# DECODER0_PVDEC_ENTROPY_HEVC register map
Vendor: Texas Instruments
Peripheral module from a debugger description file (folder J7ES).
Registers are 32-bit, read-write, reset 0x0 unless marked. A register's access mark holds for its fields unless they carry their own. Offsets are as the file gives them; lines under a group give offsets from that group; [hi:lo] are bit positions; {n}, {i} and the like mark numbered series; 'fields as' and 'values as' point back to an identical list; <NAME> marks a mode.

## DECODER0_PVDEC_ENTROPY_HEVC
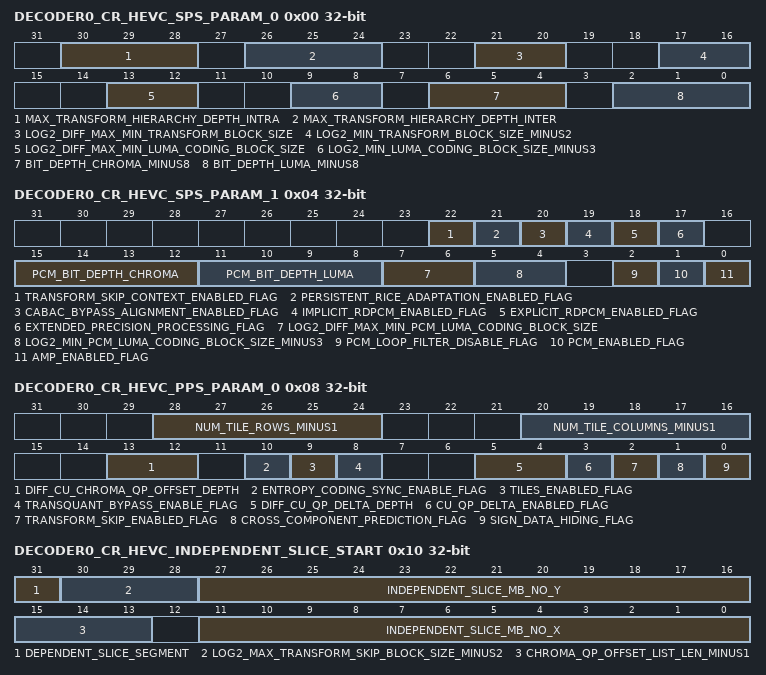
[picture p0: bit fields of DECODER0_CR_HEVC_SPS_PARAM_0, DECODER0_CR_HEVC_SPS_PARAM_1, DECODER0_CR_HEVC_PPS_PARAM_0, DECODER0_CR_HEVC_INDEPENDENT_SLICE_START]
0x00 DECODER0_CR_HEVC_SPS_PARAM_0
  [30:28] MAX_TRANSFORM_HIERARCHY_DEPTH_INTRA — Defines the maximum hierarchy depth an Intra Coded block can be split into smaller transforms [cannot be gretaer than Log2CtbSizeY [maximum is
  [26:24] MAX_TRANSFORM_HIERARCHY_DEPTH_INTER — Defines the maximum hierarchy depth an Inter Coded block can be split into smaller transforms [cannot be gretaer than Log2CtbSizeY [maximum is
  [21:20] LOG2_DIFF_MAX_MIN_TRANSFORM_BLOCK_SIZE — Defines the difference between minimum and maximum transform block size [where LOG2_MIN_TRANSFORM_BLOCK_SIZE_MINUS2 + LOG2_DIFF_MAX_MIN_TRANSFORM_BLOCK_SIZE must be &lt;= 3, and must also be less than or equal to the maximum coded block size]
  [17:16] LOG2_MIN_TRANSFORM_BLOCK_SIZE_MINUS2 — Defines the minimum transform block size [where the minimum transform block size can not be greater than the minimum luma coded block size]
  [13:12] LOG2_DIFF_MAX_MIN_LUMA_CODING_BLOCK_SIZE — Defines the difference between minimum and maximum luma coded block size, where the resulting size is sometimes refered to as the Coded Tree Unit size or CTU_SIZE [where for Main Profile, LOG2_MIN_LUMA_CODING_BLOCK_SIZE_MINUS3 + LOG2_DIFF_MAX_MIN_LUMA_CODING_BLOCK_SIZE will be in the range 1 to 3]
  [9:8] LOG2_MIN_LUMA_CODING_BLOCK_SIZE_MINUS3 — Defines the minimum luma coded block size
  [6:4] BIT_DEPTH_CHROMA_MINUS8 — 8 less than the bit depth of chroma samples
  [2:0] BIT_DEPTH_LUMA_MINUS8 — 8 less than the bit depth of luma samples
0x04 DECODER0_CR_HEVC_SPS_PARAM_1
  [22] TRANSFORM_SKIP_CONTEXT_ENABLED_FLAG — Indicates that a particular context is used for the parsing of the sig_coeff_flag for transform blocks with a skipped transform
  [21] PERSISTENT_RICE_ADAPTATION_ENABLED_FLAG — Indicates that the Rice parameter derivation for the binarization of coeff_abs_level_remaining uses a fast adaptation method
  [20] CABAC_BYPASS_ALIGNMENT_ENABLED_FLAG — Indicates CABAC alignment process is used prior to decoding coef_sign_flag and coef_abs_level_remaining syntax elements
  [19] IMPLICIT_RDPCM_ENABLED_FLAG — Indicates that the residual modification process for blocks using a transform bypass may be used for intra blocks
  [18] EXPLICIT_RDPCM_ENABLED_FLAG — Indicates that the residual modification process for blocks using a transform bypass may be used for inter blocks
  [17] EXTENDED_PRECISION_PROCESSING_FLAG — Indicates that an extended dynamic range is used for inter prediction interpolation and inverse transform processing
  [15:12] PCM_BIT_DEPTH_CHROMA — This field is 1 greater than the 'psm_sample_bit_depth_chroma_minus1' field in the bitstream, where this field can be in the range 1 to 14, but must be less than or equal to chroma sample depth
  [11:8] PCM_BIT_DEPTH_LUMA — This field is 1 greater than the 'psm_sample_bit_depth_luma_minus1' field in the bitstream, where this field can be in the range 1 to 14, but must be less than or equal to luma sample depth
  [7:6] LOG2_DIFF_MAX_MIN_PCM_LUMA_CODING_BLOCK_SIZE — If PCM is enabled, defines the difference between minimum and maximum coded block size at which PCM coding may be used [where LOG2_MIN_PCM_LUMA_CODING_BLOCK_SIZE_MINUS3 + LOG2_DIFF_MAX_MIN_PCM_LUMA_CODING_BLOCK_SIZE must be &lt;= 2]
  [5:4] LOG2_MIN_PCM_LUMA_CODING_BLOCK_SIZE_MINUS3 — If PCM is enabled, defines the minimum coded block size at which PCM coding may be used
  [2] PCM_LOOP_FILTER_DISABLE_FLAG — If PCM is enabled, this flag controls if in-loop filtering is disabled for PCM samples
  [1] PCM_ENABLED_FLAG — When set it indicates PCM coded blocks may be included in the bitstream
  [0] AMP_ENABLED_FLAG — When set it indicates PartMode of Inter prediction blocks can use asymmetric motion partitions
0x08 DECODER0_CR_HEVC_PPS_PARAM_0
  [28:24] NUM_TILE_ROWS_MINUS1 — If tiles are enabled, this field is one less than the number of tile rows the picture has been split into [where a value of zero means a tile spans the whole picture height]
  [20:16] NUM_TILE_COLUMNS_MINUS1 — If tiles are enabled, this field is one less than the number of tile columns the picture has been split into [where a value of zero means a tile spans the whole picture width]
  [13:12] DIFF_CU_CHROMA_QP_OFFSET_DEPTH — Indicates the difference between the luma coding tree block size and the minimum luma coding block size of coding units that convey cu_chroma_qp_offset_flag and cu_chroma_qp_offset_idx
  [10] ENTROPY_CODING_SYNC_ENABLE_FLAG — When set indicates CABAC state is stored after 2 CTUs in a tile row, which is then used to initialise the CABAC at the start of the next tile row
  [9] TILES_ENABLED_FLAG — When set indicates the picture is divided into tiles
  [8] TRANSQUANT_BYPASS_ENABLE_FLAG — When set indicates the cu_transquant_bypass_flag is present in the coded unit
  [5:4] DIFF_CU_QP_DELTA_DEPTH — Specifies the granularoty at which cu_qp_delta_abs may be coded in the bit stream [in the range 0 to LOG2_DIFF_MAX_MIN_LUMA_CODING_BLOCK_SIZE]
  [3] CU_QP_DELTA_ENABLED_FLAG — When set indicates cu_qp_delta_abs may be present in the transform unit syntax
  [2] TRANSFORM_SKIP_ENABLED_FLAG — When set indicates transform_skip_flag may be present in the residual coding syntax
  [1] CROSS_COMPONENT_PREDICTION_FLAG — Indicates that log2_res_scale_abs_plus1 and res_scale_sign_flag may be present in the transform unit syntax
  [0] SIGN_DATA_HIDING_FLAG — Indicates if sign bit hiding is enabled
0x10 DECODER0_CR_HEVC_INDEPENDENT_SLICE_START
  [31] DEPENDENT_SLICE_SEGMENT — If this flag is set, the current slice is a dependent slice.
  [30:28] LOG2_MAX_TRANSFORM_SKIP_BLOCK_SIZE_MINUS2 — Indicates the maximum transform block size for which transform_skip_flag may be present
  [27:16] INDEPENDENT_SLICE_MB_NO_Y — The vertical offset of the first 16x16 block in the current independent slice, or from the start of the previous independent slice if this is a dependent slice [where this field counts from 0] [For HEVC CTU sizes larger than 16x16 this is the co-ordinate of the top left 16x16 block within the CTU]
  [15:13] CHROMA_QP_OFFSET_LIST_LEN_MINUS1 — Specifies 1 less than the number of cb_qp_offset_list and cr_qp_offset_list syntax elements that are present
  [11:0] INDEPENDENT_SLICE_MB_NO_X — The horizontal offset of the first 16x16 block in the current independent slice, or from the start of the previous independent slice if this is a dependent slice [where this field counts from 0] [For HEVC CTU sizes larger than 16x16 this is the co-ordinate of the top left 16x16 block within the CTU]
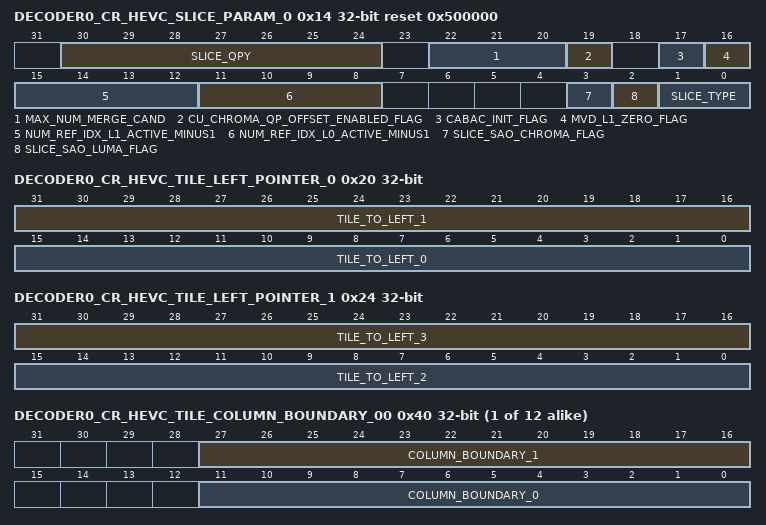
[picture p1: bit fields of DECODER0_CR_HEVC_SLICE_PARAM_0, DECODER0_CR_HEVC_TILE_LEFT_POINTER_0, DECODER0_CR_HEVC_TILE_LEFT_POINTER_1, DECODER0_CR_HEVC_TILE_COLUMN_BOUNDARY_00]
0x14 DECODER0_CR_HEVC_SLICE_PARAM_0 reset 0x500000
  [30:24] SLICE_QPY — The result of 26 + pic_init_qp_minus26 + slice_qp_delta + QpBdOffsety [which will be in the range 0 to 51+QpBdOffsety]
  [22:20] MAX_NUM_MERGE_CAND — Calcaulated from
  [19] CU_CHROMA_QP_OFFSET_ENABLED_FLAG — Indicates that the cu_chroma_qp_offset_flag may be present in the transform unit syntax
  [17] CABAC_INIT_FLAG — Either from the bit-stream, or set to 0 if it is not present
  [16] MVD_L1_ZERO_FLAG — In a B slice, when set indicates the mvd_coding syntax for list 1 is not parsed, but instead is set to 0
  [15:12] NUM_REF_IDX_L1_ACTIVE_MINUS1 — In a B slice, the field is either directly from num_ref_idx_l1_active_minus1, or inferred from num_ref_idx_l1_default_active_minus1, in the range 0 to 15
  [11:8] NUM_REF_IDX_L0_ACTIVE_MINUS1 — Field is either directly from num_ref_idx_l0_active_minus1, or inferred from num_ref_idx_l0_default_active_minus1, in the range 0 to 15
  [3] SLICE_SAO_CHROMA_FLAG — When set, indicates SAO is enabled for the chroma component in the current slice
  [2] SLICE_SAO_LUMA_FLAG — When set, indicates SAO is enabled for the luma component in the current slice
  [1:0] SLICE_TYPE — Slice type [N.B.
0x20 DECODER0_CR_HEVC_TILE_LEFT_POINTER_0 — If HEVC tiling is used, these registers keep track of the GENC fragment at the right edge of the tile to the left of the current tile. Normally these fields are updated by the hardare only. If stream switching is used, these fields can be written to restore contex.
  [31:16] TILE_TO_LEFT_1 — Fragment table entry pointer for the next tile row, for the rightmost fragment of the tile to the left, for GENC buffer 1 [not used if tiling isn't used.
  [15:0] TILE_TO_LEFT_0 — Fragment table entry pointer for the next tile row, for the rightmost fragment of the tile to the left, for GENC buffer 0 [not used if tiling isn't used.
0x24 DECODER0_CR_HEVC_TILE_LEFT_POINTER_1
  [31:16] TILE_TO_LEFT_3 — Fragment table entry pointer for the next tile row, for the rightmost fragment of the tile to the left, for GENC buffer 3 [not used if tiling isn't used.
  [15:0] TILE_TO_LEFT_2 — Fragment table entry pointer for the next tile row, for the rightmost fragment of the tile to the left, for GENC buffer 2 [not used if tiling isn't used.
{0x40+4i} DECODER0_CR_HEVC_TILE_COLUMN_BOUNDARY_{i:02} (i=0..11) — If tiles are enabled and NUM_TILE_COLUMNS_MINUS1 is greater than 0, these fields define the horizontal offset in multiples of 16x16 luma blocks to the start of each tile column (used in the calculation of which neighbouring blocks are available as well as the block co-ordinate calculation). Only the first NUM_TILE_COLUMNS_MINUS1 entries are valid. The first tile always starts at offset 0, and the last tile ends at the right edge of the picture.
  [27:16] COLUMN_BOUNDARY_1 — Tile column boundary for the 3rd, 5th, ...
  [11:0] COLUMN_BOUNDARY_0 — Tile column boundary for the 2nd, 4th, ...
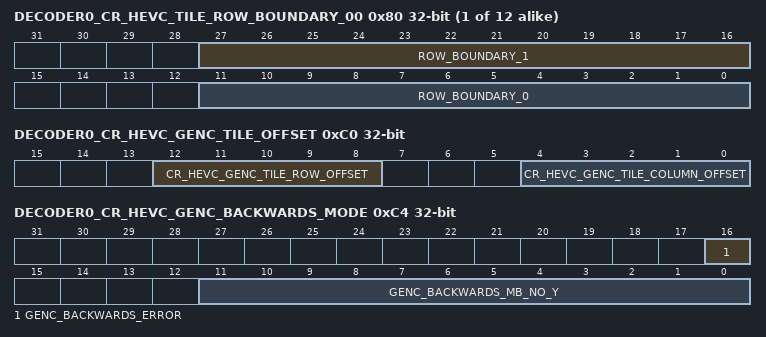
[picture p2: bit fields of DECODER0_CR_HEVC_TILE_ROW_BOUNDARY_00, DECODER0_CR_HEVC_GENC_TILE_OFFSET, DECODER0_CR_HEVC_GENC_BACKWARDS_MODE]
{0x80+4i} DECODER0_CR_HEVC_TILE_ROW_BOUNDARY_{i:02} (i=0..11) — If tiles are enabled and NUM_TILE_ROWS_MINUS1 is greater than 0, these fields define the vertical offset in multiples of 16x16 luma blocks to the start of each tile row (used in the calculation of which neighbouring blocks are available as well as the block co-ordinate calculation). Only the first NUM_TILE_ROWS_MINUS1 entries are valid. The first tile always starts at offset 0, and the last tile ends at the bottom edge of the picture.
  [27:16] ROW_BOUNDARY_1 — Tile column boundary for the 3rd, 5th, ...
  [11:0] ROW_BOUNDARY_0 — Tile column boundary for the 2nd, 4th, ...
0xC0 DECODER0_CR_HEVC_GENC_TILE_OFFSET — This register stores the offset into TILE_COLUMN_BOUNDARY_TABLE and TILE_ROW_BOUNDARY_TABLE at which the last slice finished. Normally the GENC hardware will update this field, but on a context change this register should be saved and restored.
  [12:8] CR_HEVC_GENC_TILE_ROW_OFFSET — The offset to the entry in TILE_ROW_BOUNDARY_TABLE at which the last slice finished
  [4:0] CR_HEVC_GENC_TILE_COLUMN_OFFSET — The offset to the entry in TILE_COLUMN_BOUNDARY_TABLE at which the last slice finished
0xC4 DECODER0_CR_HEVC_GENC_BACKWARDS_MODE — This register stores information on the GENC encoder backwards error correction mode - a flag to indicate the mode is in use, and the last macroblock row on which backwards error correction will be active. This will be one tile to the right of the row one before the start of the slice that caused the backwards step, or the bottom row of a tile at the right edge of the picture if that occurs sooner.Normally the GENC hardware will update these fields, but on a context change this register should be saved and restored.
  [16] GENC_BACKWARDS_ERROR — When set, indicates the GENC encoder is in backwards error correction mode.
  [11:0] GENC_BACKWARDS_MB_NO_Y — Indicates the last macroblock row for backwards error correction.
